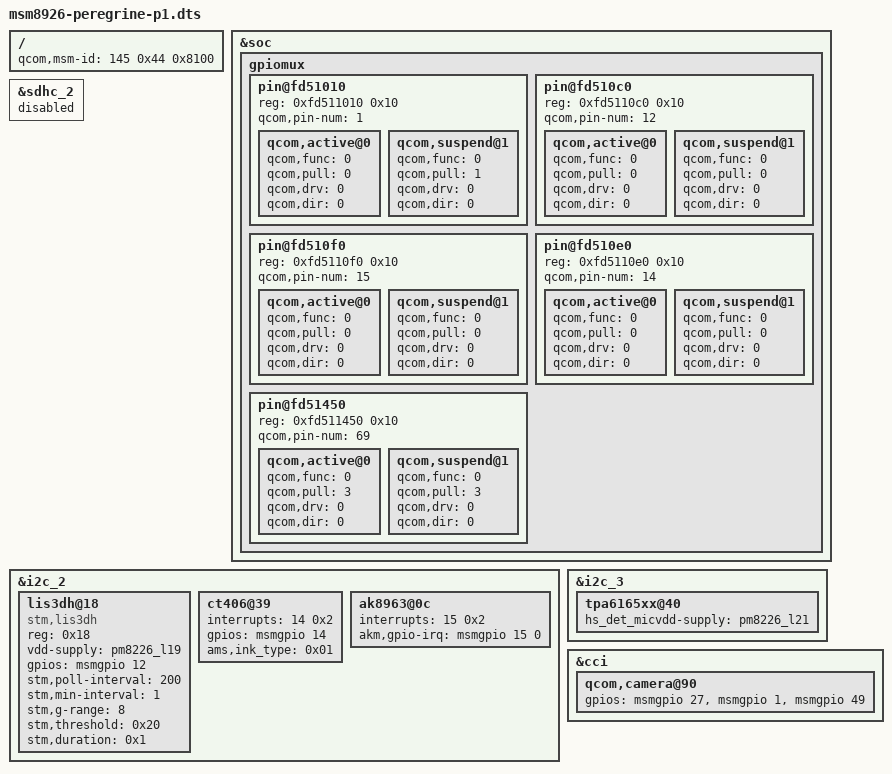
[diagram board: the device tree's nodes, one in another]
/* Copyright (c) 2013, Motorola Mobility LLC
 *
 * This program is free software; you can redistribute it and/or modify
 * it under the terms of the GNU General Public License version 2 and
 * only version 2 as published by the Free Software Foundation.
 *
 * This program is distributed in the hope that it will be useful,
 * but WITHOUT ANY WARRANTY; without even the implied warranty of
 * MERCHANTABILITY or FITNESS FOR A PARTICULAR PURPOSE.  See the
 * GNU General Public License for more details.
 */

/dts-v1/;

/include/ "msm8226-moto-reserve.dtsi"
/include/ "msm8926.dtsi"
/include/ "msm8926-peregrine-common.dtsi"

/ {
	qcom,msm-id = <145 0x44 0x8100>;
};

&soc {
	gpiomux {
		pin@fd51010 {
			reg = <0xfd511010 0x10>;	/* CAM_F_C_EN */
			qcom,pin-num = <1>;
			qcom,active@0 {
				qcom,func = <0>;  /* gpio_in_out(1)         */
				qcom,pull = <0>;  /* none                   */
				qcom,drv = <0>;   /* 2ma                    */
				qcom,dir = <0>;   /* input                  */
			};
			qcom,suspend@1 {
				qcom,func = <0>;  /* gpio_in_out(1)         */
				qcom,pull = <1>;  /* down                   */
				qcom,drv = <0>;   /* 2ma                    */
				qcom,dir = <0>;   /* input                  */
			};
		};

		pin@fd510c0 {
			reg = <0xfd5110c0 0x10>;	/* ACCL_INT_N */
			qcom,pin-num = <12>;
			qcom,active@0 {
				qcom,func = <0>;  /* gpio_in_out(12)        */
				qcom,pull = <0>;  /* none                   */
				qcom,drv = <0>;   /* 2ma                    */
				qcom,dir = <0>;   /* input                  */
			};
			qcom,suspend@1 {
				qcom,func = <0>;  /* gpio_in_out(12)        */
				qcom,pull = <0>;  /* none                   */
				qcom,drv = <0>;   /* 2ma                    */
				qcom,dir = <0>;   /* input                  */
			};
		};

		pin@fd510f0 {
			reg = <0xfd5110f0 0x10>;	/* COMPASS_INT */
			qcom,pin-num = <15>;
			qcom,active@0 {
				qcom,func = <0>;  /* gpio_in_out(15)        */
				qcom,pull = <0>;  /* none                   */
				qcom,drv = <0>;   /* 2ma                    */
				qcom,dir = <0>;   /* input                  */
			};
			qcom,suspend@1 {
				qcom,func = <0>;  /* gpio_in_out(15)        */
				qcom,pull = <0>;  /* none                   */
				qcom,drv = <0>;   /* 2ma                    */
				qcom,dir = <0>;   /* input                  */
			};
		};

		pin@fd510e0 {
			reg = <0xfd5110e0 0x10>;	/* IR_PROX_INT */
			qcom,pin-num = <14>;
			qcom,active@0 {
				qcom,func = <0>;  /* gpio_in_out(14)        */
				qcom,pull = <0>;  /* none                   */
				qcom,drv = <0>;   /* 2ma                    */
				qcom,dir = <0>;   /* input                  */
			};
			qcom,suspend@1 {
				qcom,func = <0>;  /* gpio_in_out(14)        */
				qcom,pull = <0>;  /* none                   */
				qcom,drv = <0>;   /* 2ma                    */
				qcom,dir = <0>;   /* input                  */
			};
		};

		pin@fd51450 {
			reg = <0xfd511450 0x10>;	/* USR_RST_WARN_N */
			qcom,pin-num = <69>;
			qcom,active@0 {
				qcom,func = <0>;  /* gpio_in_out(69)        */
				qcom,pull = <3>;  /* up                     */
				qcom,drv = <0>;   /* 2ma                    */
				qcom,dir = <0>;   /* input                  */
			};
			qcom,suspend@1 {
				qcom,func = <0>;  /* gpio_in_out(69)        */
				qcom,pull = <3>;  /* up                     */
				qcom,drv = <0>;   /* 2ma                    */
				qcom,dir = <0>;   /* input                  */
			};
		};

	};
};

&sdhc_2 {
	status = "disabled";
};

&i2c_2 {
	lis3dh@18 {
		compatible = "stm,lis3dh";
		reg = <0x18>;
		vdd-supply = <&pm8226_l19>;
		gpios = <&msmgpio 12 0>; /* IRQ */
		stm,poll-interval = <200>;
		stm,min-interval = <1>;
		stm,g-range = <8>;
		stm,threshold = <0x20>;
		stm,duration = <0x1>;
	};

	ct406@39 {
		interrupts = <14 0x2>;
		gpios = <&msmgpio 14 0>;
		ams,ink_type = <0x01>;
	};

	ak8963@0c {
		interrupts = <15 0x2>;
		akm,gpio-irq = <&msmgpio 15 0>;
	};
};

&i2c_3 {
	tpa6165xx@40 {
		hs_det_micvdd-supply = <&pm8226_l21>;
	};
};

&cci {
	qcom,camera@90 {
		gpios = <&msmgpio 27 0>,
			<&msmgpio 1 0>,
			<&msmgpio 49 0>;
	};
};
